VERSION "HNPBNNNYYNYNNYYNNNNNNNNNNNNNNNYNNNNYNNNNNN/4/%%%/4/'%**4NNN///"

NS_ :

BS_:

BU_: AS Other

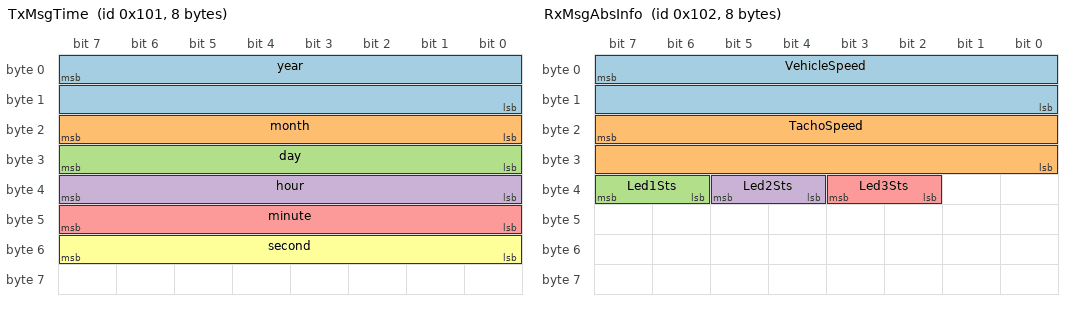
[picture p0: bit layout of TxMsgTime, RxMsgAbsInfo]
BO_ 257 TxMsgTime: 8 AS
SG_ year : 7|16@0+ (1,0) [0|4294967295] "" AS
SG_ month : 23|8@0+ (1,0) [0|4294967295] "" AS
SG_ day : 31|8@0+ (1,0) [0|4294967295] "" AS
SG_ hour : 39|8@0+ (1,0) [0|4294967295] "" AS
SG_ minute : 47|8@0+ (1,0) [0|4294967295] "" AS
SG_ second : 55|8@0+ (1,0) [0|4294967295] "" AS

BO_ 258 RxMsgAbsInfo: 8 Other
SG_ VehicleSpeed : 7|16@0+ (1,0) [0|4294967295] "" Other
SG_ TachoSpeed : 23|16@0+ (1,0) [0|4294967295] "" Other
SG_ Led1Sts : 39|2@0+ (1,0) [0|4294967295] "" Other
SG_ Led2Sts : 37|2@0+ (1,0) [0|4294967295] "" Other
SG_ Led3Sts : 35|2@0+ (1,0) [0|4294967295] "" Other
